# MKM14ZA5 register map
Vendor: Freescale Semiconductor, Inc.; Series: Kinetis_M; File version: 1.6
CPU: CM0PLUS r0p0, little endian, no MPU, no FPU, VTOR, 2 interrupt priority bits
Registers are 8-bit, read-write, reset 0x0 unless marked. A register's access mark holds for its fields unless they carry their own. Offsets are from the block's base; [hi:lo] are bit positions; {n}, {i} and the like mark numbered series.

## DMAMUX0 — DMA channel multiplexor
Base 0x40021000; register names take the prefix DMAMUX0_
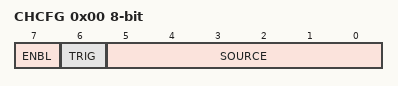
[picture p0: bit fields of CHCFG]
0x00 CHCFG — Channel Configuration register
  [7] ENBL — DMA Channel Enable
    0=DMA channel is disabled. This mode is primarily used during configuration of the DMAMux. The DMA has separate channel enables/disables, which should be used to disable or reconfigure a DMA channel.; 1=DMA channel is enabled
  [6] TRIG — DMA Channel Trigger Enable
    0=Triggering is disabled. If triggering is disabled and ENBL is set, the DMA Channel will simply route the specified source to the DMA channel. (Normal mode); 1=Triggering is enabled. If triggering is enabled and ENBL is set, the DMAMUX is in Periodic Trigger mode.
  [5:0] SOURCE — DMA Channel Source (Slot)

## DMAMUX1 — DMA channel multiplexor
Base 0x40022000; register names take the prefix DMAMUX1_
Registers as DMAMUX0.

## DMAMUX2 — DMA channel multiplexor
Base 0x40023000; register names take the prefix DMAMUX2_
Registers as DMAMUX0.

## DMAMUX3 — DMA channel multiplexor
Base 0x40024000; register names take the prefix DMAMUX3_
Registers as DMAMUX0.

## RNG — Random Number Generator Accelerator
Base 0x40029000; register names take the prefix RNG_
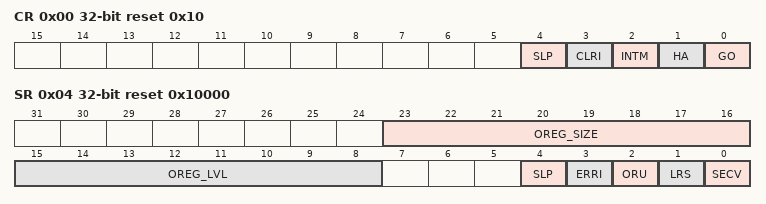
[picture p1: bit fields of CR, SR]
0x00 CR 32-bit reset 0x10 — RNGA Control Register
  [4] SLP — Sleep
    0=Normal mode; 1=Sleep (low-power) mode
  [3] CLRI wo — Clear Interrupt
    0=Do not clear the interrupt; 1=Clear the interrupt. When you write 1 to this field, RNGA then resets the error-interrupt indicator (SR[ERRI]). This bit always reads as 0.
  [2] INTM — Interrupt Mask
    0=Not masked; 1=Masked
  [1] HA — High Assurance
    0=Disabled; 1=Enabled
  [0] GO
    0=Disabled; 1=Enabled
0x04 SR 32-bit ro reset 0x10000 — RNGA Status Register
  [23:16] OREG_SIZE — Output Register Size
    1=One word (this value is fixed)
  [15:8] OREG_LVL — Output Register Level
    0=No words (empty); 1=One word (valid)
  [4] SLP — Sleep
    0=Normal mode; 1=Sleep (low-power) mode
  [3] ERRI — Error Interrupt
    0=No underflow; 1=Underflow
  [2] ORU — Output Register Underflow
    0=No underflow; 1=Underflow
  [1] LRS — Last Read Status
    0=No underflow; 1=Underflow
  [0] SECV — Security Violation
    0=No security violation; 1=Security violation
0x08 ER 32-bit wo — RNGA Entropy Register
  [31:0] EXT_ENT — External Entropy
0x0C OR 32-bit ro — RNGA Output Register
  [31:0] RANDOUT — Random Output
    0=Invalid data (if you read this field when it is 0 and SR[OREG_LVL] is 0, RNGA then writes 1 to SR[ERRI], SR[ORU], and SR[LRS]; when the error interrupt is not masked (CR[INTM]=0), RNGA also asserts an error interrupt request to the interrupt controller)

## PIT0 — Periodic Interrupt Timer
Base 0x4002D000; register names take the prefix PIT0_
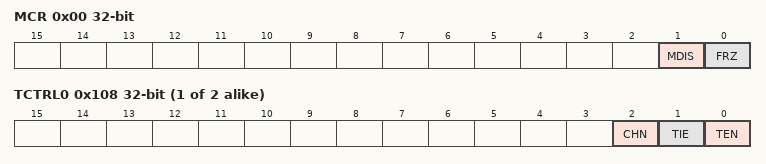
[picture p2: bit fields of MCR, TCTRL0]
0x00 MCR 32-bit — PIT Module Control Register
  [1] MDIS — Module Disable - (PIT section)
    0=Clock for standard PIT timers is enabled; 1=Clock for standard PIT timers is disabled
  [0] FRZ — Freeze
    0=Timers continue to run in Debug mode; 1=Timers are stopped in Debug mode
{0x100+0x10*i} LDVAL{i} (i=0..1) 32-bit — Timer Load Value Register
  [31:0] TSV — Timer Start Value
{0x104+0x10*i} CVAL{i} (i=0..1) 32-bit ro — Current Timer Value Register
  [31:0] TVL — Current Timer Value
{0x108+0x10*i} TCTRL{i} (i=0..1) 32-bit — Timer Control Register
  [2] CHN — Chain Mode
    0=Timer is not chained; 1=Timer is chained to previous timer. For example, for Channel 2, if this field is set, Timer 2 is chained to Timer 1.
  [1] TIE — Timer Interrupt Enable
    0=Interrupt requests from Timer n are disabled; 1=Interrupt will be requested whenever TIF is set
  [0] TEN — Timer Enable
    0=Timer n is disabled; 1=Timer n is enabled
{0x10C+0x10*i} TFLG{i} (i=0..1) 32-bit — Timer Flag Register
  [0] TIF — Timer Interrupt Flag
    0=Timeout has not yet occurred; 1=Timeout has occurred

## PIT1 — Periodic Interrupt Timer
Base 0x4002E000; register names take the prefix PIT1_
Registers as PIT0.

## Notices in the file
Redistribution and use in source and binary forms, with or without modification,
are permitted provided that the following conditions are met:
o Redistributions of source code must retain the above copyright notice, this list
of conditions and the following disclaimer.
o Redistributions in binary form must reproduce the above copyright notice, this
list of conditions and the following disclaimer in the documentation and/or
other materials provided with the distribution.
o Neither the name of Freescale Semiconductor, Inc. nor the names of its
contributors may be used to endorse or promote products derived from this
software without specific prior written permission.
THIS SOFTWARE IS PROVIDED BY THE COPYRIGHT HOLDERS AND CONTRIBUTORS "AS IS" AND
ANY EXPRESS OR IMPLIED WARRANTIES, INCLUDING, BUT NOT LIMITED TO, THE IMPLIED
WARRANTIES OF MERCHANTABILITY AND FITNESS FOR A PARTICULAR PURPOSE ARE
DISCLAIMED. IN NO EVENT SHALL THE COPYRIGHT HOLDER OR CONTRIBUTORS BE LIABLE FOR
ANY DIRECT, INDIRECT, INCIDENTAL, SPECIAL, EXEMPLARY, OR CONSEQUENTIAL DAMAGES
(INCLUDING, BUT NOT LIMITED TO, PROCUREMENT OF SUBSTITUTE GOODS OR SERVICES;
LOSS OF USE, DATA, OR PROFITS; OR BUSINESS INTERRUPTION) HOWEVER CAUSED AND ON
ANY THEORY OF LIABILITY, WHETHER IN CONTRACT, STRICT LIABILITY, OR TORT
(INCLUDING NEGLIGENCE OR OTHERWISE) ARISING IN ANY WAY OUT OF THE USE OF THIS
SOFTWARE, EVEN IF ADVISED OF THE POSSIBILITY OF SUCH DAMAGE.
